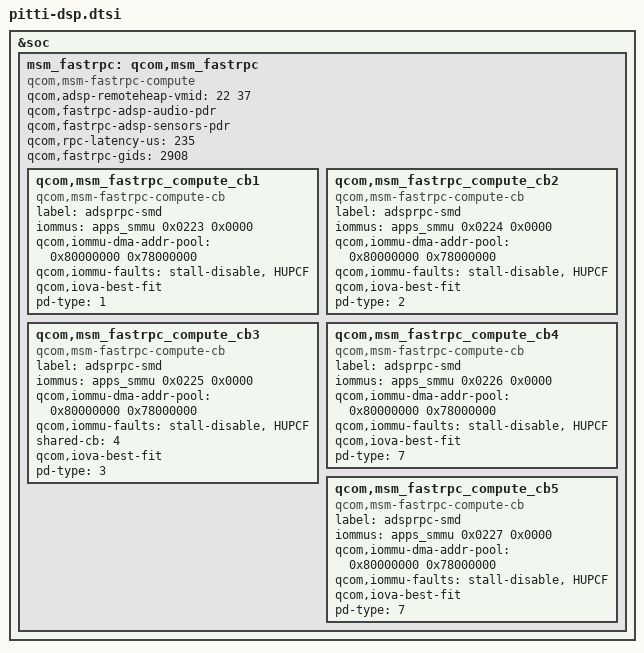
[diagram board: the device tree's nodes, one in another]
&soc {

	msm_fastrpc: qcom,msm_fastrpc {
		compatible = "qcom,msm-fastrpc-compute";
		qcom,adsp-remoteheap-vmid = <22 37>;
		qcom,fastrpc-adsp-audio-pdr;
		qcom,fastrpc-adsp-sensors-pdr;
		qcom,rpc-latency-us = <235>;
		qcom,fastrpc-gids = <2908>;

		qcom,msm_fastrpc_compute_cb1 {
			compatible = "qcom,msm-fastrpc-compute-cb";
			label = "adsprpc-smd";
			iommus = <&apps_smmu 0x0223 0x0000>;
			qcom,iommu-dma-addr-pool = <0x80000000 0x78000000>;
			qcom,iommu-faults = "stall-disable", "HUPCF";
			qcom,iova-best-fit;
			pd-type = <1>;	/* ROOT_PD */
		};

		qcom,msm_fastrpc_compute_cb2 {
			compatible = "qcom,msm-fastrpc-compute-cb";
			label = "adsprpc-smd";
			iommus = <&apps_smmu 0x0224 0x0000>;
			qcom,iommu-dma-addr-pool = <0x80000000 0x78000000>;
			qcom,iommu-faults = "stall-disable", "HUPCF";
			qcom,iova-best-fit;
			pd-type = <2>;	/* AUDIO_STATICPD */
		};

		qcom,msm_fastrpc_compute_cb3 {
			compatible = "qcom,msm-fastrpc-compute-cb";
			label = "adsprpc-smd";
			iommus = <&apps_smmu 0x0225 0x0000>;
			qcom,iommu-dma-addr-pool = <0x80000000 0x78000000>;
			qcom,iommu-faults = "stall-disable", "HUPCF";
			shared-cb = <4>;
			qcom,iova-best-fit;
			pd-type = <3>;	/* SENSORS_STATICPD */
		};

		qcom,msm_fastrpc_compute_cb4 {
			compatible = "qcom,msm-fastrpc-compute-cb";
			label = "adsprpc-smd";
			iommus = <&apps_smmu 0x0226 0x0000>;
			qcom,iommu-dma-addr-pool = <0x80000000 0x78000000>;
			qcom,iommu-faults = "stall-disable", "HUPCF";
			qcom,iova-best-fit;
			pd-type = <7>;	/* USERPD */
		};

		qcom,msm_fastrpc_compute_cb5 {
			compatible = "qcom,msm-fastrpc-compute-cb";
			label = "adsprpc-smd";
			iommus = <&apps_smmu 0x0227 0x0000>;
			qcom,iommu-dma-addr-pool = <0x80000000 0x78000000>;
			qcom,iommu-faults = "stall-disable", "HUPCF";
			qcom,iova-best-fit;
			pd-type = <7>;	/* USERPD */
		};
	};
};
